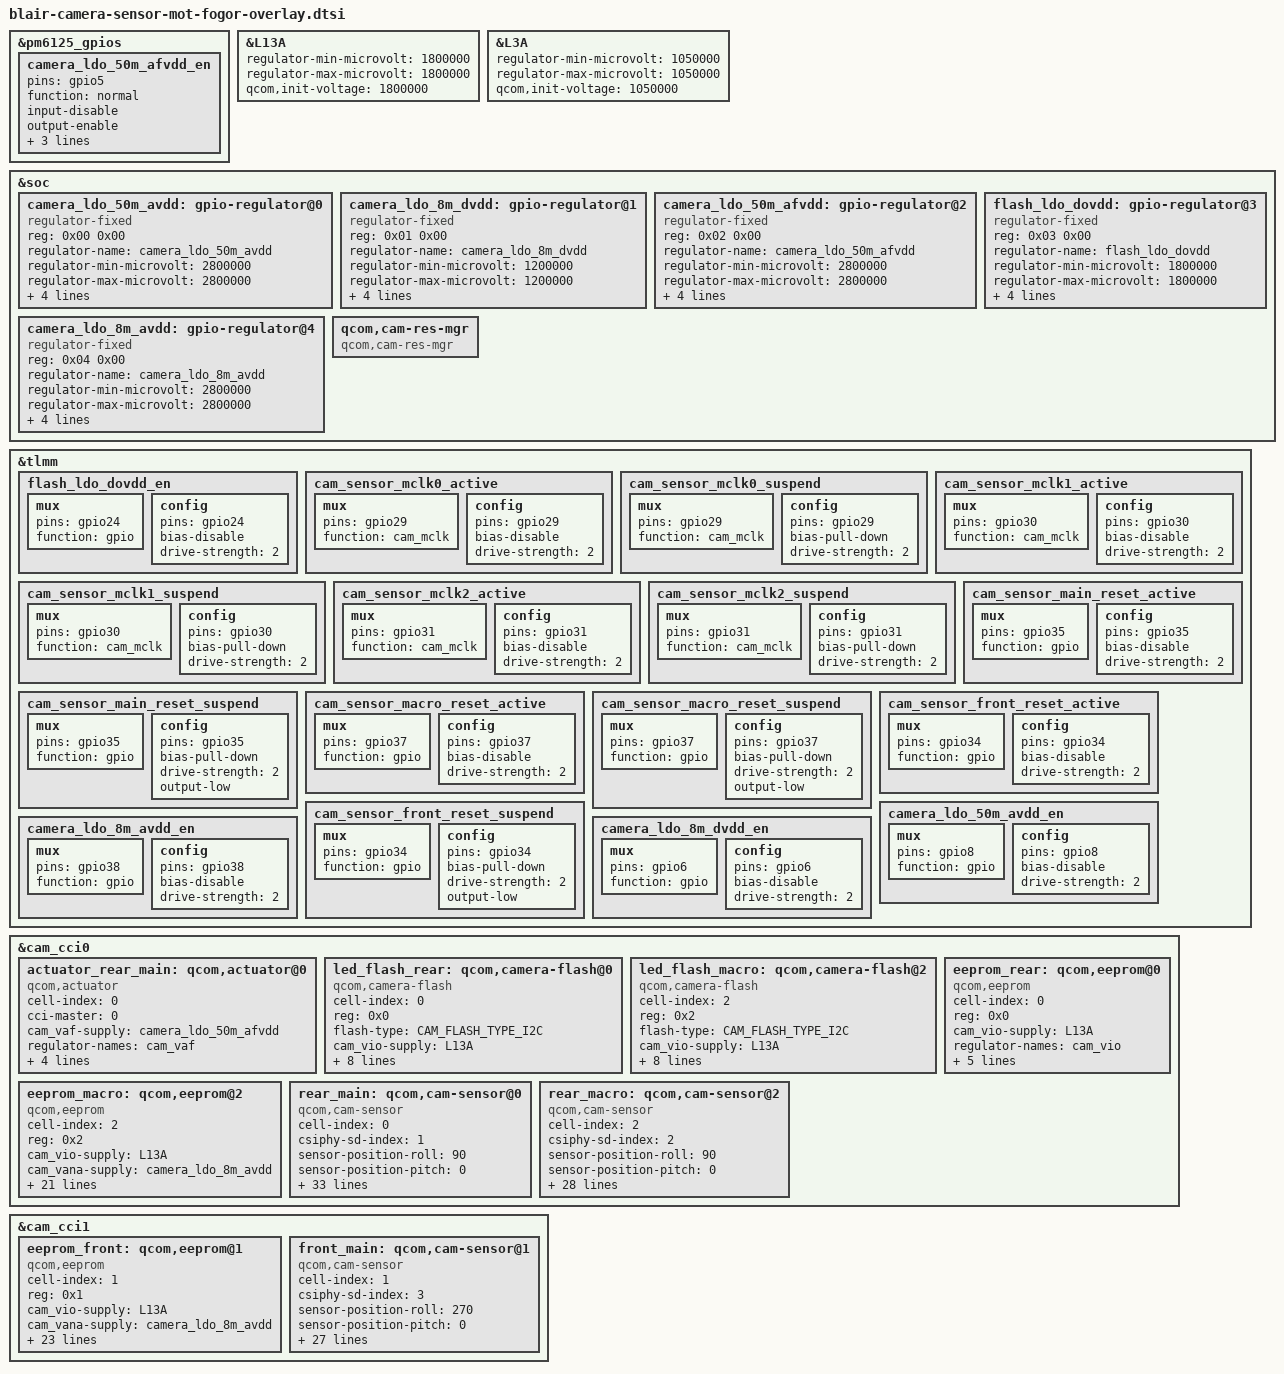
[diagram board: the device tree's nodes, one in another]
#include <dt-bindings/clock/qcom,gcc-blair.h>
#include <dt-bindings/msm/msm-camera.h>

&pm6125_gpios {
  camera_ldo_50m_afvdd_en: camera_ldo_50m_afvdd_en {
    pins = "gpio5";
    function = "normal";
    input-disable;
    output-enable;
    bias-pull-down; /* PULL DOWN */
    power-source = <0>; /* 1.8V */
    qcom,drive-strength = <2>; /* Medium */
  };
};

/*s5kjns s5k4h7 sc202acs iovdd*/
&L13A{
  regulator-min-microvolt = <1800000>;
  regulator-max-microvolt = <1800000>;
  qcom,init-voltage = <1800000>;
  status = "okay";
};

/*s5kjns dvdd*/
&L3A{
  regulator-min-microvolt = <1050000>;
  regulator-max-microvolt = <1050000>;
  qcom,init-voltage = <1050000>;
  status = "okay";
};

&soc {
  /*s5kjns avdd*/
  camera_ldo_50m_avdd: gpio-regulator@0 {
    compatible = "regulator-fixed";
    reg = <0x00 0x00>;
    regulator-name = "camera_ldo_50m_avdd";
    regulator-min-microvolt = <2800000>;
    regulator-max-microvolt = <2800000>;
    regulator-enable-ramp-delay = <233>;
    enable-active-high;
    gpio = <&tlmm 8 0>;
    pinctrl-names = "default";
    pinctrl-0 = <&camera_ldo_50m_avdd_en>;
  };

  /*s5k4h7 dvdd*/
  camera_ldo_8m_dvdd: gpio-regulator@1 {
    compatible = "regulator-fixed";
    reg = <0x01 0x00>;
    regulator-name = "camera_ldo_8m_dvdd";
    regulator-min-microvolt = <1200000>;
    regulator-max-microvolt = <1200000>;
    regulator-enable-ramp-delay = <233>;
    enable-active-high;
    gpio = <&tlmm 6 0>;
    pinctrl-names = "default";
    pinctrl-0 = <&camera_ldo_8m_dvdd_en>;
  };

  camera_ldo_50m_afvdd: gpio-regulator@2 {
    compatible = "regulator-fixed";
    reg = <0x02 0x00>;
    regulator-name = "camera_ldo_50m_afvdd";
    regulator-min-microvolt = <2800000>;
    regulator-max-microvolt = <2800000>;
    regulator-enable-ramp-delay = <233>;
    enable-active-high;
    gpio = <&pm6125_gpios 5 0>;
    pinctrl-names = "default";
    pinctrl-0 = <&camera_ldo_50m_afvdd_en>;
  };

  flash_ldo_dovdd: gpio-regulator@3 {
    compatible = "regulator-fixed";
    reg = <0x03 0x00>;
    regulator-name = "flash_ldo_dovdd";
    regulator-min-microvolt = <1800000>;
    regulator-max-microvolt = <1800000>;
    regulator-enable-ramp-delay = <233>;
    enable-active-high;
    gpio = <&tlmm 24 0>;
    pinctrl-names = "default";
    pinctrl-0 = <&flash_ldo_dovdd_en>;
  };

  camera_ldo_8m_avdd: gpio-regulator@4 {
    compatible = "regulator-fixed";
    reg = <0x04 0x00>;
    regulator-name = "camera_ldo_8m_avdd";
    regulator-min-microvolt = <2800000>;
    regulator-max-microvolt = <2800000>;
    regulator-enable-ramp-delay = <233>;
    enable-active-high;
    gpio = <&tlmm 38 0>;
    pinctrl-names = "default";
    pinctrl-0 = <&camera_ldo_8m_avdd_en>;
  };

  qcom,cam-res-mgr {
    compatible = "qcom,cam-res-mgr";
    status = "ok";
  };
};

&tlmm {
  flash_ldo_dovdd_en: flash_ldo_dovdd_en {
    mux {
      pins = "gpio24";
      function = "gpio";
    };

    config {
      pins = "gpio24";
      bias-disable; /* No PULL */
      drive-strength = <2>; /* 2 MA */
    };
  };

  cam_sensor_mclk0_active: cam_sensor_mclk0_active {
    mux {
      pins = "gpio29";
      function = "cam_mclk";
    };

    config {
      pins = "gpio29";
      bias-disable; /* No PULL */
      drive-strength = <2>; /* 2 MA */
    };
  };

  cam_sensor_mclk0_suspend: cam_sensor_mclk0_suspend {
    mux {
      pins = "gpio29";
      function = "cam_mclk";
    };

    config {
      pins = "gpio29";
      bias-pull-down; /* PULL DOWN */
      drive-strength = <2>; /* 2 MA */
    };
  };

  cam_sensor_mclk1_active: cam_sensor_mclk1_active {
    mux {
      pins = "gpio30";
      function = "cam_mclk";
    };

    config {
      pins = "gpio30";
      bias-disable; /* No PULL */
      drive-strength = <2>; /* 2 MA */
    };
  };

  cam_sensor_mclk1_suspend: cam_sensor_mclk1_suspend {
    mux {
      pins = "gpio30";
      function = "cam_mclk";
    };

    config {
      pins = "gpio30";
      bias-pull-down; /* PULL DOWN */
      drive-strength = <2>; /* 2 MA */
    };
  };

  cam_sensor_mclk2_active: cam_sensor_mclk2_active {
    mux {
      pins = "gpio31";
      function = "cam_mclk";
    };

    config {
      pins = "gpio31";
      bias-disable; /* No PULL */
      drive-strength = <2>;
    };
  };

  cam_sensor_mclk2_suspend: cam_sensor_mclk2_suspend {
    mux {
      pins = "gpio31";
      function = "cam_mclk";
    };

    config {
      pins = "gpio31";
      bias-pull-down; /* PULL DOWN */
      drive-strength = <2>;
    };
  };

  cam_sensor_main_reset_active: cam_sensor_main_reset_active {
    mux {
      pins = "gpio35";
      function = "gpio";
    };

    config {
      pins = "gpio35";
      bias-disable; /* No PULL */
      drive-strength = <2>; /* 2 MA */
    };
  };

  cam_sensor_main_reset_suspend: cam_sensor_main_reset_suspend {
    mux {
      pins = "gpio35";
      function = "gpio";
    };

    config {
      pins = "gpio35";
      bias-pull-down; /* PULL DOWN */
      drive-strength = <2>; /* 2 MA */
      output-low;
    };
  };
  cam_sensor_macro_reset_active: cam_sensor_macro_reset_active {
    mux {
      pins = "gpio37";
      function = "gpio";
    };

    config {
      pins = "gpio37";
      bias-disable; /* No PULL */
      drive-strength = <2>; /* 2 MA */
    };
  };

  cam_sensor_macro_reset_suspend: cam_sensor_macro_reset_suspend {
    mux {
      pins = "gpio37";
      function = "gpio";
    };

    config {
      pins = "gpio37";
      bias-pull-down; /* PULL DOWN */
      drive-strength = <2>; /* 2 MA */
      output-low;
    };
  };
  cam_sensor_front_reset_active: cam_sensor_front_reset_active {
    mux {
      pins = "gpio34";
      function = "gpio";
    };

    config {
      pins = "gpio34";
      bias-disable; /* No PULL */
      drive-strength = <2>; /* 2 MA */
    };
  };

  cam_sensor_front_reset_suspend: cam_sensor_front_reset_suspend {
    mux {
      pins = "gpio34";
      function = "gpio";
    };

    config {
      pins = "gpio34";
      bias-pull-down; /* PULL DOWN */
      drive-strength = <2>; /* 2 MA */
      output-low;
    };
  };

/* s5kjns avdd enable */
  camera_ldo_50m_avdd_en: camera_ldo_50m_avdd_en {
    mux {
      pins = "gpio8";
      function = "gpio";
    };

    config {
      pins = "gpio8";
      bias-disable; /* No PULL */
      drive-strength = <2>; /* 2 MA */
    };
  };

  camera_ldo_8m_avdd_en: camera_ldo_8m_avdd_en {
    mux {
      pins = "gpio38";
      function = "gpio";
    };

    config {
      pins = "gpio38";
      bias-disable; /* No PULL */
      drive-strength = <2>; /* 2 MA */
    };
  };

/* s5k4h7 dvdd enable */
  camera_ldo_8m_dvdd_en: camera_ldo_8m_dvdd_en {
    mux {
      pins = "gpio6";
      function = "gpio";
    };

    config {
      pins = "gpio6";
      bias-disable; /* No PULL */
      drive-strength = <2>; /* 2 MA */
    };
  };
};

&cam_cci0 {
  /* Rear 50M AF */
  actuator_rear_main: qcom,actuator@0{
    cell-index = <0>;
    compatible = "qcom,actuator";
    cci-master = <0>;
    cam_vaf-supply = <&camera_ldo_50m_afvdd>;
    regulator-names = "cam_vaf";
    rgltr-cntrl-support;
    rgltr-min-voltage = <2800000>;
    rgltr-max-voltage = <2800000>;
    rgltr-load-current = <103000>;
    status = "ok";
  };


  /* Rear s5kjns FLASH */
  led_flash_rear: qcom,camera-flash@0 {
    cell-index = <0>;
    reg = <0x0>;
    compatible = "qcom,camera-flash";
    flash-type = <CAM_FLASH_TYPE_I2C>;
    cam_vio-supply = <&L13A>;
    cam_v_custom2-supply = <&flash_ldo_dovdd>;
    regulator-names = "cam_vio","cam_v_custom2";
    rgltr-cntrl-support;
    rgltr-min-voltage = <1800000 1800000>;
    rgltr-max-voltage = <1800000 1800000>;
    rgltr-load-current = <100000 120000>;
    distinguish-flash-supplier = <0xc6 0x0c 0x3a>;
    cci-master = <1>;
    status = "ok";
  };

  /* MACRO sc202acs FLASH */
  led_flash_macro: qcom,camera-flash@2 {
    cell-index = <2>;
    reg = <0x2>;
    compatible = "qcom,camera-flash";
    flash-type = <CAM_FLASH_TYPE_I2C>;
    cam_vio-supply = <&L13A>;
    cam_v_custom2-supply = <&flash_ldo_dovdd>;
    regulator-names = "cam_vio","cam_v_custom2";
    rgltr-cntrl-support;
    rgltr-min-voltage = <1800000 1800000>;
    rgltr-max-voltage = <1800000 1800000>;
    rgltr-load-current = <100000 120000>;
    distinguish-flash-supplier = <0xc6 0x0c 0x3a>;
    cci-master = <1>;
    status = "ok";
  };

  /* Rear s5kjns eeprom */
  eeprom_rear: qcom,eeprom@0 {
    cell-index = <0>;
    reg = <0x0>;
    compatible = "qcom,eeprom";
    cam_vio-supply = <&L13A>;
    regulator-names = "cam_vio";
    rgltr-cntrl-support;
    rgltr-min-voltage = <1800000>;
    rgltr-max-voltage = <1800000>;
    rgltr-load-current = <120000>;
    cci-master = <0>;
    status = "ok";
  };

  /* Rear sc202acs eeprom */
  eeprom_macro: qcom,eeprom@2 {
    cell-index = <2>;
    reg = <0x2>;
    compatible = "qcom,eeprom";
    cam_vio-supply = <&L13A>;
    cam_vana-supply = <&camera_ldo_8m_avdd>;
    cam_clk-supply = <&gcc_camss_top_gdsc>;
    regulator-names = "cam_vio", "cam_vana", "cam_clk";
    rgltr-cntrl-support;
    rgltr-min-voltage = <1800000 2800000 0>;
    rgltr-max-voltage = <1800000 2800000 0>;
    rgltr-load-current = <120000 80000 0>;
    gpio-no-mux = <0>;
    pinctrl-names = "cam_default", "cam_suspend";
    pinctrl-0 = <&cam_sensor_mclk2_active &cam_sensor_macro_reset_active>;
    pinctrl-1 = <&cam_sensor_mclk2_suspend &cam_sensor_macro_reset_suspend>;
    gpios = <&tlmm 31 0>, <&tlmm 37 0>;
    gpio-reset = <1>;
    gpio-req-tbl-num = <0 1 >;
    gpio-req-tbl-flags = <1 0 >;
    gpio-req-tbl-label = "CAMIF_MCLK2", "CAM_RESET3";
    sensor-mode = <0>;
    cci-master = <1>;
    status = "ok";
    clocks = <&gcc GCC_CAMSS_MCLK2_CLK>;
    clock-names = "cam_clk";
    clock-cntl-level = "turbo";
    clock-rates = <24000000>;
  };

  /* Rear s5kjns */
  rear_main: qcom,cam-sensor@0 {
    cell-index = <0>;
    compatible = "qcom,cam-sensor";
    csiphy-sd-index = <1>;
    sensor-position-roll = <90>;
    sensor-position-pitch = <0>;
    sensor-position-yaw = <180>;
    actuator-src = <&actuator_rear_main>;
    eeprom-src = <&eeprom_rear>;
    led-flash-src = <&led_flash_rear>;
    cam_v_custom2-supply = <&flash_ldo_dovdd>;
    cam_vio-supply = <&L13A>;
    cam_vana-supply = <&camera_ldo_50m_avdd>;
    cam_vdig-supply = <&L3A>;
    cam_clk-supply = <&gcc_camss_top_gdsc>;
    cam_vaf-supply = <&camera_ldo_50m_afvdd>;
    regulator-names ="cam_v_custom2", "cam_vio", "cam_vana", "cam_vdig", "cam_clk", "cam_vaf";
    rgltr-cntrl-support;
    rgltr-min-voltage = <1800000 1800000 2800000 1050000 0 2800000>;
    rgltr-max-voltage = <1800000 1800000 2800000 1050000 0 2800000>;
    rgltr-load-current = <120000 120000 80000 1200000 0 103000>;
    gpio-no-mux = <0>;
    pinctrl-names = "cam_default", "cam_suspend";
    pinctrl-0 = <&cam_sensor_mclk0_active &cam_sensor_main_reset_active>;
    pinctrl-1 = <&cam_sensor_mclk0_suspend &cam_sensor_main_reset_suspend>;
    gpios = <&tlmm 29 0>, <&tlmm 35 0>;
    gpio-reset = <1>;
    gpio-req-tbl-num = <0 1>;
    gpio-req-tbl-flags = <1 0>;
    gpio-req-tbl-label = "CAMIF_MCLK0", "CAM_RESET1";
    cci-master = <0>;
    status = "ok";
    clocks = <&gcc GCC_CAMSS_MCLK0_CLK>;
    clock-names = "cam_clk";
    clock-cntl-level = "turbo";
    clock-rates = <24000000>;
  };

  /* Rear sc202acs */
  rear_macro: qcom,cam-sensor@2 {
    cell-index = <2>;
    compatible = "qcom,cam-sensor";
    csiphy-sd-index = <2>;
    sensor-position-roll = <90>;
    sensor-position-pitch = <0>;
    sensor-position-yaw = <180>;
    eeprom-src = <&eeprom_macro>;
    led-flash-src = <&led_flash_macro>;
    cam_v_custom2-supply = <&flash_ldo_dovdd>;
    cam_vio-supply = <&L13A>;
    cam_vana-supply = <&camera_ldo_8m_avdd>;
    cam_clk-supply = <&gcc_camss_top_gdsc>;
    regulator-names = "cam_v_custom2", "cam_vio", "cam_vana", "cam_clk";
    rgltr-cntrl-support;
    rgltr-min-voltage = <1800000 1800000 2800000 0>;
    rgltr-max-voltage = <1800000 1800000 2800000 0>;
    rgltr-load-current = <120000 120000 80000 0>;
    gpio-no-mux = <0>;
    pinctrl-names = "cam_default", "cam_suspend";
    pinctrl-0 = <&cam_sensor_mclk2_active &cam_sensor_macro_reset_active>;
    pinctrl-1 = <&cam_sensor_mclk2_suspend &cam_sensor_macro_reset_suspend>;
    gpios = <&tlmm 31 0>, <&tlmm 37 0>;
    gpio-reset = <1>;
    gpio-req-tbl-num = <0 1 >;
    gpio-req-tbl-flags = <1 0 >;
    gpio-req-tbl-label = "CAMIF_MCLK2", "CAM_RESET3";
    sensor-mode = <0>;
    cci-master = <1>;
    status = "ok";
    clocks = <&gcc GCC_CAMSS_MCLK2_CLK>;
    clock-names = "cam_clk";
    clock-cntl-level = "turbo";
    clock-rates = <24000000>;
  };
};

&cam_cci1 {
  /* Front s5k4h7 otp */
  eeprom_front: qcom,eeprom@1 {
    cell-index = <1>;
    reg = <0x1>;
    compatible = "qcom,eeprom";
    cam_vio-supply = <&L13A>;
    cam_vana-supply = <&camera_ldo_8m_avdd>;
    cam_vdig-supply = <&camera_ldo_8m_dvdd>;
    cam_clk-supply = <&gcc_camss_top_gdsc>;
    regulator-names = "cam_vio", "cam_vana", "cam_vdig", "cam_clk";
    rgltr-cntrl-support;
    rgltr-min-voltage = <1800000 2800000 1200000 0>;
    rgltr-max-voltage = <1800000 2800000 1200000 0>;
    rgltr-load-current = <120000 80000 1200000 0>;
    gpio-no-mux = <0>;
    pinctrl-names = "cam_default", "cam_suspend";
    pinctrl-0 = <&cam_sensor_mclk1_active &cam_sensor_front_reset_active>;
    pinctrl-1 = <&cam_sensor_mclk1_suspend &cam_sensor_front_reset_suspend>;
    gpios = <&tlmm 30 0>, <&tlmm 34 0>;
    gpio-reset = <1>;
    gpio-req-tbl-num = <0 1 >;
    gpio-req-tbl-flags = <1 0 >;
    gpio-req-tbl-label = "CAMIF_MCLK1", "CAM_RESET0";
    sensor-mode = <1>;
    cci-master = <0>;
    status = "ok";
    clocks = <&gcc GCC_CAMSS_MCLK1_CLK>;
    clock-names = "cam_clk";
    clock-cntl-level = "turbo";
    clock-rates = <24000000>;
  };

  /*Front s5k4h7*/
  front_main: qcom,cam-sensor@1 {
    cell-index = <1>;
    compatible = "qcom,cam-sensor";
    csiphy-sd-index = <3>;
    sensor-position-roll = <270>;
    sensor-position-pitch = <0>;
    sensor-position-yaw = <0>;
    eeprom-src = <&eeprom_front>;
    cam_vio-supply = <&L13A>;
    cam_vana-supply = <&camera_ldo_8m_avdd>;
    cam_vdig-supply = <&camera_ldo_8m_dvdd>;
    cam_clk-supply = <&gcc_camss_top_gdsc>;
    regulator-names = "cam_vio", "cam_vana", "cam_vdig", "cam_clk";
    rgltr-cntrl-support;
    rgltr-min-voltage = <1800000 2800000 1200000 0>;
    rgltr-max-voltage = <1800000 2800000 1200000 0>;
    rgltr-load-current = <120000 80000 1200000 0>;
    gpio-no-mux = <0>;
    pinctrl-names = "cam_default", "cam_suspend";
    pinctrl-0 = <&cam_sensor_mclk1_active &cam_sensor_front_reset_active>;
    pinctrl-1 = <&cam_sensor_mclk1_suspend &cam_sensor_front_reset_suspend>;
    gpios = <&tlmm 30 0>, <&tlmm 34 0>;
    gpio-reset = <1>;
    gpio-req-tbl-num = <0 1 >;
    gpio-req-tbl-flags = <1 0 >;
    gpio-req-tbl-label = "CAMIF_MCLK1", "CAM_RESET0";
    sensor-mode = <1>;
    cci-master = <0>;
    status = "ok";
    clocks = <&gcc GCC_CAMSS_MCLK1_CLK>;
    clock-names = "cam_clk";
    clock-cntl-level = "turbo";
    clock-rates = <24000000>;
  };
};
